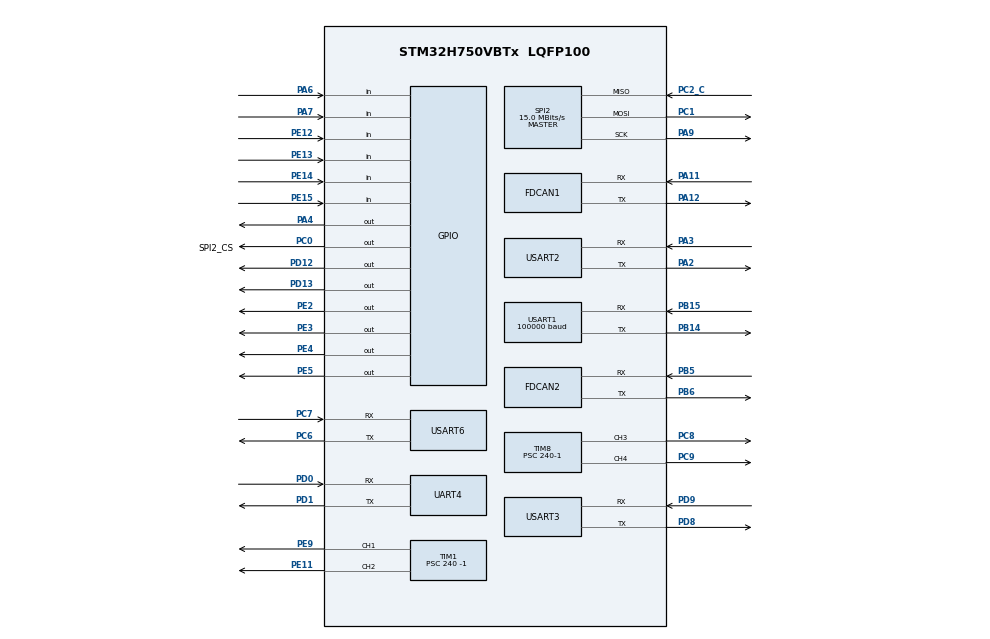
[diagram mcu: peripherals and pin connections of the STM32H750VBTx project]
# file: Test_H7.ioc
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Dma.Request0=USART1_RX
Dma.Request1=USART2_RX
Dma.Request2=USART2_TX
Dma.Request3=USART3_RX
Dma.Request4=USART3_TX
Dma.Request5=USART6_RX
Dma.Request6=USART6_TX
Dma.Request7=USART1_TX
Dma.USART1_RX.0.Direction=DMA_PERIPH_TO_MEMORY
Dma.USART1_RX.0.EventEnable=DISABLE
Dma.USART1_RX.0.FIFOMode=DMA_FIFOMODE_DISABLE
Dma.USART1_RX.0.Instance=DMA2_Stream2
Dma.USART1_RX.0.MemDataAlignment=DMA_MDATAALIGN_BYTE
Dma.USART1_RX.0.MemInc=DMA_MINC_ENABLE
Dma.USART1_RX.0.Mode=DMA_CIRCULAR
Dma.USART1_RX.0.PeriphDataAlignment=DMA_PDATAALIGN_BYTE
Dma.USART1_RX.0.PeriphInc=DMA_PINC_DISABLE
Dma.USART1_RX.0.Polarity=HAL_DMAMUX_REQ_GEN_RISING
Dma.USART1_RX.0.Priority=DMA_PRIORITY_VERY_HIGH
Dma.USART1_RX.0.RequestNumber=1
Dma.USART1_RX.0.SignalID=NONE
Dma.USART1_RX.0.SyncEnable=DISABLE
Dma.USART1_RX.0.SyncPolarity=HAL_DMAMUX_SYNC_NO_EVENT
Dma.USART1_RX.0.SyncRequestNumber=1
Dma.USART1_RX.0.SyncSignalID=NONE
Dma.USART1_TX.7.Direction=DMA_MEMORY_TO_PERIPH
Dma.USART1_TX.7.EventEnable=DISABLE
Dma.USART1_TX.7.FIFOMode=DMA_FIFOMODE_DISABLE
Dma.USART1_TX.7.Instance=DMA1_Stream0
Dma.USART1_TX.7.MemDataAlignment=DMA_MDATAALIGN_BYTE
Dma.USART1_TX.7.MemInc=DMA_MINC_ENABLE
Dma.USART1_TX.7.Mode=DMA_NORMAL
Dma.USART1_TX.7.PeriphDataAlignment=DMA_PDATAALIGN_BYTE
Dma.USART1_TX.7.PeriphInc=DMA_PINC_DISABLE
Dma.USART1_TX.7.Polarity=HAL_DMAMUX_REQ_GEN_RISING
Dma.USART1_TX.7.Priority=DMA_PRIORITY_LOW
Dma.USART1_TX.7.RequestNumber=1
Dma.USART1_TX.7.SignalID=NONE
Dma.USART1_TX.7.SyncEnable=DISABLE
Dma.USART1_TX.7.SyncPolarity=HAL_DMAMUX_SYNC_NO_EVENT
Dma.USART1_TX.7.SyncRequestNumber=1
Dma.USART1_TX.7.SyncSignalID=NONE
Dma.USART2_RX.1.Direction=DMA_PERIPH_TO_MEMORY
Dma.USART2_RX.1.EventEnable=DISABLE
Dma.USART2_RX.1.FIFOMode=DMA_FIFOMODE_DISABLE
Dma.USART2_RX.1.Instance=DMA1_Stream2
Dma.USART2_RX.1.MemDataAlignment=DMA_MDATAALIGN_BYTE
Dma.USART2_RX.1.MemInc=DMA_MINC_ENABLE
Dma.USART2_RX.1.Mode=DMA_CIRCULAR
Dma.USART2_RX.1.PeriphDataAlignment=DMA_PDATAALIGN_BYTE
Dma.USART2_RX.1.PeriphInc=DMA_PINC_DISABLE
Dma.USART2_RX.1.Polarity=HAL_DMAMUX_REQ_GEN_RISING
Dma.USART2_RX.1.Priority=DMA_PRIORITY_HIGH
Dma.USART2_RX.1.RequestNumber=1
Dma.USART2_RX.1.SignalID=NONE
Dma.USART2_RX.1.SyncEnable=DISABLE
Dma.USART2_RX.1.SyncPolarity=HAL_DMAMUX_SYNC_NO_EVENT
Dma.USART2_RX.1.SyncRequestNumber=1
Dma.USART2_RX.1.SyncSignalID=NONE
Dma.USART2_TX.2.Direction=DMA_MEMORY_TO_PERIPH
Dma.USART2_TX.2.EventEnable=DISABLE
Dma.USART2_TX.2.FIFOMode=DMA_FIFOMODE_DISABLE
Dma.USART2_TX.2.Instance=DMA1_Stream4
Dma.USART2_TX.2.MemDataAlignment=DMA_MDATAALIGN_BYTE
Dma.USART2_TX.2.MemInc=DMA_MINC_ENABLE
Dma.USART2_TX.2.Mode=DMA_NORMAL
Dma.USART2_TX.2.PeriphDataAlignment=DMA_PDATAALIGN_BYTE
Dma.USART2_TX.2.PeriphInc=DMA_PINC_DISABLE
Dma.USART2_TX.2.Polarity=HAL_DMAMUX_REQ_GEN_RISING
Dma.USART2_TX.2.Priority=DMA_PRIORITY_HIGH
Dma.USART2_TX.2.RequestNumber=1
Dma.USART2_TX.2.SignalID=NONE
Dma.USART2_TX.2.SyncEnable=DISABLE
Dma.USART2_TX.2.SyncPolarity=HAL_DMAMUX_SYNC_NO_EVENT
Dma.USART2_TX.2.SyncRequestNumber=1
Dma.USART2_TX.2.SyncSignalID=NONE
Dma.USART3_RX.3.Direction=DMA_PERIPH_TO_MEMORY
Dma.USART3_RX.3.EventEnable=DISABLE
Dma.USART3_RX.3.FIFOMode=DMA_FIFOMODE_DISABLE
Dma.USART3_RX.3.Instance=DMA1_Stream1
Dma.USART3_RX.3.MemDataAlignment=DMA_MDATAALIGN_BYTE
Dma.USART3_RX.3.MemInc=DMA_MINC_ENABLE
Dma.USART3_RX.3.Mode=DMA_CIRCULAR
Dma.USART3_RX.3.PeriphDataAlignment=DMA_PDATAALIGN_BYTE
Dma.USART3_RX.3.PeriphInc=DMA_PINC_DISABLE
Dma.USART3_RX.3.Polarity=HAL_DMAMUX_REQ_GEN_RISING
Dma.USART3_RX.3.Priority=DMA_PRIORITY_VERY_HIGH
Dma.USART3_RX.3.RequestNumber=1
Dma.USART3_RX.3.SignalID=NONE
Dma.USART3_RX.3.SyncEnable=DISABLE
Dma.USART3_RX.3.SyncPolarity=HAL_DMAMUX_SYNC_NO_EVENT
Dma.USART3_RX.3.SyncRequestNumber=1
Dma.USART3_RX.3.SyncSignalID=NONE
Dma.USART3_TX.4.Direction=DMA_MEMORY_TO_PERIPH
Dma.USART3_TX.4.EventEnable=DISABLE
Dma.USART3_TX.4.FIFOMode=DMA_FIFOMODE_DISABLE
Dma.USART3_TX.4.Instance=DMA1_Stream3
Dma.USART3_TX.4.MemDataAlignment=DMA_MDATAALIGN_BYTE
Dma.USART3_TX.4.MemInc=DMA_MINC_ENABLE
Dma.USART3_TX.4.Mode=DMA_NORMAL
Dma.USART3_TX.4.PeriphDataAlignment=DMA_PDATAALIGN_BYTE
Dma.USART3_TX.4.PeriphInc=DMA_PINC_DISABLE
Dma.USART3_TX.4.Polarity=HAL_DMAMUX_REQ_GEN_RISING
Dma.USART3_TX.4.Priority=DMA_PRIORITY_VERY_HIGH
Dma.USART3_TX.4.RequestNumber=1
Dma.USART3_TX.4.SignalID=NONE
Dma.USART3_TX.4.SyncEnable=DISABLE
Dma.USART3_TX.4.SyncPolarity=HAL_DMAMUX_SYNC_NO_EVENT
Dma.USART3_TX.4.SyncRequestNumber=1
Dma.USART3_TX.4.SyncSignalID=NONE
Dma.USART6_RX.5.Direction=DMA_PERIPH_TO_MEMORY
Dma.USART6_RX.5.EventEnable=DISABLE
Dma.USART6_RX.5.FIFOMode=DMA_FIFOMODE_DISABLE
Dma.USART6_RX.5.Instance=DMA2_Stream1
Dma.USART6_RX.5.MemDataAlignment=DMA_MDATAALIGN_BYTE
Dma.USART6_RX.5.MemInc=DMA_MINC_ENABLE
Dma.USART6_RX.5.Mode=DMA_CIRCULAR
Dma.USART6_RX.5.PeriphDataAlignment=DMA_PDATAALIGN_BYTE
Dma.USART6_RX.5.PeriphInc=DMA_PINC_DISABLE
Dma.USART6_RX.5.Polarity=HAL_DMAMUX_REQ_GEN_RISING
Dma.USART6_RX.5.Priority=DMA_PRIORITY_VERY_HIGH
Dma.USART6_RX.5.RequestNumber=1
Dma.USART6_RX.5.SignalID=NONE
Dma.USART6_RX.5.SyncEnable=DISABLE
Dma.USART6_RX.5.SyncPolarity=HAL_DMAMUX_SYNC_NO_EVENT
Dma.USART6_RX.5.SyncRequestNumber=1
Dma.USART6_RX.5.SyncSignalID=NONE
Dma.USART6_TX.6.Direction=DMA_MEMORY_TO_PERIPH
Dma.USART6_TX.6.EventEnable=DISABLE
Dma.USART6_TX.6.FIFOMode=DMA_FIFOMODE_DISABLE
Dma.USART6_TX.6.Instance=DMA2_Stream6
Dma.USART6_TX.6.MemDataAlignment=DMA_MDATAALIGN_BYTE
Dma.USART6_TX.6.MemInc=DMA_MINC_ENABLE
Dma.USART6_TX.6.Mode=DMA_NORMAL
Dma.USART6_TX.6.PeriphDataAlignment=DMA_PDATAALIGN_BYTE
Dma.USART6_TX.6.PeriphInc=DMA_PINC_DISABLE
Dma.USART6_TX.6.Polarity=HAL_DMAMUX_REQ_GEN_RISING
Dma.USART6_TX.6.Priority=DMA_PRIORITY_VERY_HIGH
Dma.USART6_TX.6.RequestNumber=1
Dma.USART6_TX.6.SignalID=NONE
Dma.USART6_TX.6.SyncEnable=DISABLE
Dma.USART6_TX.6.SyncPolarity=HAL_DMAMUX_SYNC_NO_EVENT
Dma.USART6_TX.6.SyncRequestNumber=1
Dma.USART6_TX.6.SyncSignalID=NONE
FDCAN1.AutoRetransmission=DISABLE
FDCAN1.DataPrescaler=1
FDCAN1.DataSyncJumpWidth=10
FDCAN1.DataTimeSeg1=29
FDCAN1.DataTimeSeg2=10
FDCAN1.ExtFiltersNbr=1
FDCAN1.FrameFormat=FDCAN_FRAME_FD_BRS
FDCAN1.Mode=FDCAN_MODE_NORMAL
FDCAN1.NominalPrescaler=1
FDCAN1.NominalSyncJumpWidth=8
FDCAN1.NominalTimeSeg1=31
FDCAN1.NominalTimeSeg2=8
FDCAN1.RxBufferSize=FDCAN_DATA_BYTES_8
FDCAN1.RxBuffersNbr=0
FDCAN1.RxFifo0ElmtSize=FDCAN_DATA_BYTES_8
FDCAN1.RxFifo0ElmtsNbr=32
FDCAN1.RxFifo1ElmtSize=FDCAN_DATA_BYTES_8
FDCAN1.RxFifo1ElmtsNbr=0
FDCAN1.StdFiltersNbr=1
FDCAN1.TransmitPause=DISABLE
FDCAN1.TxBuffersNbr=0
FDCAN1.TxElmtSize=FDCAN_DATA_BYTES_8
FDCAN1.TxEventsNbr=0
FDCAN1.TxFifoQueueElmtsNbr=8
FDCAN2.DataSyncJumpWidth=10
FDCAN2.DataTimeSeg1=29
FDCAN2.DataTimeSeg2=10
FDCAN2.ExtFiltersNbr=1
FDCAN2.FrameFormat=FDCAN_FRAME_FD_BRS
FDCAN2.MessageRAMOffset=666
FDCAN2.NominalSyncJumpWidth=8
FDCAN2.NominalTimeSeg1=31
FDCAN2.NominalTimeSeg2=8
FDCAN2.RxFifo0ElmtsNbr=32
FDCAN2.StdFiltersNbr=1
FDCAN2.TxFifoQueueElmtsNbr=8
FREERTOS.Tasks01=defaultTask,0,128,StartDefaultTask,Default,NULL,Dynamic,NULL,NULL;FireTask,1,128,Fire_Task,As external,NULL,Dynamic,NULL,NULL;LedTask,-3,128,Led_Task,As external,NULL,Dynamic,NULL,NULL;DetectTASK,-1,128,Detect_TASK,As external,NULL,Dynamic,NULL,NULL;SAFETASK,1,128,SAFE_TASK,As external,NULL,Dynamic,NULL,NULL;RemoteTask,2,128,Remote_Task,As external,NULL,Dynamic,NULL,NULL
Mcu.Family=STM32H7
Mcu.Name=STM32H750VBTx
Mcu.Package=LQFP100
NVIC.DMA1_Stream0_IRQn=true\:5\:0\:false\:false\:true\:true\:false\:true
NVIC.DMA1_Stream1_IRQn=true\:5\:0\:false\:false\:true\:true\:false\:true
NVIC.DMA1_Stream2_IRQn=true\:5\:0\:false\:false\:true\:false\:false\:true
NVIC.DMA1_Stream3_IRQn=true\:5\:0\:false\:false\:true\:true\:false\:true
NVIC.DMA1_Stream4_IRQn=true\:5\:0\:false\:false\:true\:true\:false\:true
NVIC.DMA2_Stream1_IRQn=true\:5\:0\:false\:false\:true\:false\:false\:true
NVIC.DMA2_Stream2_IRQn=true\:5\:0\:false\:false\:true\:true\:false\:true
NVIC.DMA2_Stream6_IRQn=true\:5\:0\:false\:false\:true\:false\:false\:true
NVIC.FDCAN1_IT0_IRQn=true\:5\:0\:false\:false\:true\:true\:true\:true
NVIC.FDCAN2_IT0_IRQn=true\:5\:0\:false\:false\:true\:true\:true\:true
NVIC.PriorityGroup=NVIC_PRIORITYGROUP_4
NVIC.TIM2_IRQn=true\:15\:0\:false\:false\:true\:false\:false\:true
NVIC.TimeBase=TIM2_IRQn
NVIC.TimeBaseIP=TIM2
NVIC.USART1_IRQn=true\:5\:0\:false\:false\:true\:true\:true\:true
NVIC.USART2_IRQn=true\:5\:0\:false\:false\:true\:true\:true\:true
NVIC.USART3_IRQn=true\:5\:0\:false\:false\:true\:true\:true\:true
NVIC.USART6_IRQn=true\:5\:0\:false\:false\:true\:true\:true\:true
PA11.Mode=FDCAN_Activate
PA11.Signal=FDCAN1_RX
PA12.Mode=FDCAN_Activate
PA12.Signal=FDCAN1_TX
PA13\ (JTMS/SWDIO).Mode=Serial_Wire
PA13\ (JTMS/SWDIO).Signal=DEBUG_JTMS-SWDIO
PA14\ (JTCK/SWCLK).Mode=Serial_Wire
PA14\ (JTCK/SWCLK).Signal=DEBUG_JTCK-SWCLK
PA2.Mode=Asynchronous
PA2.Signal=USART2_TX
PA3.GPIO_PuPd=GPIO_PULLUP
PA3.Mode=Asynchronous
PA3.Signal=USART2_RX
PA4.Signal=GPIO_Output
PA6.GPIO_PuPd=GPIO_PULLDOWN
PA6.Signal=GPIO_Input
PA7.GPIO_PuPd=GPIO_PULLDOWN
PA7.Signal=GPIO_Input
PA9.Mode=Full_Duplex_Master
PA9.Signal=SPI2_SCK
PB14.Mode=Asynchronous
PB14.Signal=USART1_TX
PB15.Mode=Asynchronous
PB15.Signal=USART1_RX
PB5.Mode=FDCAN_Activate
PB5.Signal=FDCAN2_RX
PB6.Mode=FDCAN_Activate
PB6.Signal=FDCAN2_TX
PC0.GPIO_Label=SPI2_CS
PC0.Signal=GPIO_Output
PC1.Mode=Full_Duplex_Master
PC1.Signal=SPI2_MOSI
PC2_C.Mode=Full_Duplex_Master
PC2_C.Signal=SPI2_MISO
PC6.Mode=Asynchronous
PC6.Signal=USART6_TX
PC7.Mode=Asynchronous
PC7.Signal=USART6_RX
PC8.Signal=S_TIM8_CH3
PC9.Signal=S_TIM8_CH4
PD0.Mode=Asynchronous
PD0.Signal=UART4_RX
PD1.Mode=Asynchronous
PD1.Signal=UART4_TX
PD12.GPIO_PuPd=GPIO_PULLUP
PD12.GPIO_Speed=GPIO_SPEED_FREQ_HIGH
PD12.Signal=GPIO_Output
PD13.GPIO_PuPd=GPIO_PULLUP
PD13.GPIO_Speed=GPIO_SPEED_FREQ_HIGH
PD13.Signal=GPIO_Output
PD8.Mode=Asynchronous
PD8.Signal=USART3_TX
PD9.Mode=Asynchronous
PD9.Signal=USART3_RX
PE11.Signal=S_TIM1_CH2
PE12.GPIO_PuPd=GPIO_NOPULL
PE12.Signal=GPIO_Input
PE13.Signal=GPIO_Input
PE14.Signal=GPIO_Input
PE15.Signal=GPIO_Input
PE2.PinState=GPIO_PIN_SET
PE2.Signal=GPIO_Output
PE3.Signal=GPIO_Output
PE4.Signal=GPIO_Output
PE5.Signal=GPIO_Output
PE9.GPIO_PuPd=GPIO_PULLUP
PE9.Signal=S_TIM1_CH1
PH0-OSC_IN\ (PH0).Mode=HSE-External-Oscillator
PH0-OSC_IN\ (PH0).Signal=RCC_OSC_IN
PH1-OSC_OUT\ (PH1).Mode=HSE-External-Oscillator
PH1-OSC_OUT\ (PH1).Signal=RCC_OSC_OUT
ProjectManager.HeapSize=0x200
ProjectManager.StackSize=0x400
ProjectManager.TargetToolchain=MDK-ARM V5.32
RCC.ADCFreq_Value=60000000
RCC.APB1Freq_Value=120000000
RCC.APB2Freq_Value=120000000
RCC.APB3Freq_Value=120000000
RCC.APB4Freq_Value=120000000
RCC.CKPERSourceSelection=RCC_CLKPSOURCE_HSE
RCC.CortexFreq_Value=480000000
RCC.D1PPRE=RCC_APB3_DIV2
RCC.D2PPRE1=RCC_APB1_DIV2
RCC.D2PPRE2=RCC_APB2_DIV2
RCC.D3PPRE=RCC_APB4_DIV2
RCC.DIVM1=5
RCC.DIVM2=25
RCC.DIVM3=25
RCC.DIVN1=192
RCC.DIVN2=480
RCC.DIVN3=480
RCC.DIVP2=8
RCC.DIVQ1=24
RCC.HCLKFreq_Value=240000000
RCC.HPRE=RCC_HCLK_DIV2
RCC.PLLFRACN=0
RCC.PLLSourceVirtual=RCC_PLLSOURCE_HSE
RCC.SPI123CLockSelection=RCC_SPI123CLKSOURCE_PLL2
RCC.SYSCLKFreq_VALUE=480000000
RCC.SYSCLKSource=RCC_SYSCLKSOURCE_PLLCLK
RCC.USBFreq_Value=40000000
SH.S_TIM1_CH1.0=TIM1_CH1,PWM Generation1 CH1
SH.S_TIM1_CH2.0=TIM1_CH2,PWM Generation2 CH2
SH.S_TIM8_CH3.0=TIM8_CH3,PWM Generation3 CH3
SH.S_TIM8_CH4.0=TIM8_CH4,PWM Generation4 CH4
SPI2.BaudRatePrescaler=SPI_BAUDRATEPRESCALER_4
SPI2.CalculateBaudRate=15.0 MBits/s
SPI2.DataSize=SPI_DATASIZE_8BIT
SPI2.Direction=SPI_DIRECTION_2LINES
SPI2.Mode=SPI_MODE_MASTER
SPI2.VirtualType=VM_MASTER
TIM1.Channel-PWM\ Generation1\ CH1=TIM_CHANNEL_1
TIM1.Channel-PWM\ Generation2\ CH2=TIM_CHANNEL_2
TIM1.Period=2100
TIM1.Prescaler=240 -1 
TIM8.Channel-PWM\ Generation3\ CH3=TIM_CHANNEL_3
TIM8.Channel-PWM\ Generation4\ CH4=TIM_CHANNEL_4
TIM8.Period=2100
TIM8.Prescaler=240-1
USART1.BaudRate=100000
USART1.Parity=PARITY_EVEN
USART1.VirtualMode-Asynchronous=VM_ASYNC
USART1.WordLength=WORDLENGTH_9B
USART2.VirtualMode-Asynchronous=VM_ASYNC
USART3.VirtualMode-Asynchronous=VM_ASYNC
USART6.VirtualMode=VM_ASYNC
VP_FREERTOS_VS_CMSIS_V1.Mode=CMSIS_V1
VP_RNG_VS_RNG.Mode=RNG_Activate
VP_SYS_VS_tim2.Mode=TIM2
board=custom

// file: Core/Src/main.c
/* USER CODE BEGIN Header */
/**
  ******************************************************************************
  * @file           : main.c
  * @brief          : Main program body
  ******************************************************************************
  * @attention
  *
  * <h2><center>&copy; Copyright (c) 2021 STMicroelectronics.
  * All rights reserved.</center></h2>
  *
  * This software component is licensed by ST under BSD 3-Clause license,
  * the "License"; You may not use this file except in compliance with the
  * License. You may obtain a copy of the License at:
  *                        opensource.org/licenses/BSD-3-Clause
  *
  ******************************************************************************
  */
/* USER CODE END Header */
#include "main.h"
#include "cmsis_os.h"
#include "dma.h"
#include "fdcan.h"
#include "rng.h"
#include "spi.h"
#include "tim.h"
#include "usart.h"
#include "gpio.h"

/* USER CODE BEGIN Includes */
#include "SysInit.h"
/* USER CODE END Includes */

/* USER CODE BEGIN PTD */

/************************** Dongguan-University of Technology -ACE**************************
 *@project   SentryChassis
 *@Author    Dongguan-University of Technology  ACE  Ҷ��͢Y.Z.T.
 *@Date      2022-01-07

                    P                          :u7  :Ii              .
                   QBQ                     sQBBQBB  PBBBBQI.        XQBBBBBBBBBQBBBBBBBBBBBBM
                  bBBBZ                 .MQBQBBBQB  5BBBBBBBBi      uBBBBBBBBBQBBBBBBBBBQBBBP
                 bBBQQB5               XBBBRQQBBBP  sQBQBQQBBBZ     IBBBBBBBBBBBBBBBBBBBBBBBD
                 rBBgRQBY             BBQQRBBQr        rgBBBQr
               .  iBBgRQB7           BBQRgBQ:            iE.
              :BY  7BBgRQB:         sBQMgBB
             .BBB:  uBBgRBB.        BBMDQQ:                         rSU57  UQPdPbPPPPqPPbPdQs
             BBQBB:  XBQgRBB        QBggQB                          sBEQ1  QBBBBQBBBBBBBBBBBZ
            BBQgBBB   KBRDRBB       BBgDBB                          jBDQU  QBBBBBBBBBBBQBBBBg
           BBQgRBB     dQggQBB      BBggQB.                         iXJS7  uDK5XXK5KXKXXSSXg7
          gBQgRQB   BBggQDggQBQ     YBQDMBB
         PBQgRBB   BBBBBRQgMgQBg     BBQgRBB:            iZ:
        2BQgMBB.  BBBBBBBBBQRgQBK     BBBRQBBQL.      .rRBBQBr       ..                   ..
       vQBgRQB:  :uriiiiiirBQQgBB1     XQBQQQBBBBE  uBQBQBQBBBD     SBBBBBBBBBBBBBBBBBBBQBBBD
      7QBQBBBr             :BBBQBBY     .ZBQBBBBBB  qBBQBBBBB:      UBBBBQBBBBBBBBBBBBBBBBBBd
     LBBBBBBJ               7BBBBBQu       YRBBBQB  KBBBBBJ.        IBQBBBBBQBBBBBBBBBBBBBBBZ
                                                7i  .7.
*************************** Dongguan-University of Technology -ACE**************************/

/* USER CODE END PTD */

void SystemClock_Config(void);
void MX_FREERTOS_Init(void);

int main(void)
{

  /* MCU Configuration--------------------------------------------------------*/

  /* Reset of all peripherals, Initializes the Flash interface and the Systick. */
  HAL_Init();

  /* Configure the system clock */
  SystemClock_Config();

  /* Initialize all configured peripherals */
  MX_GPIO_Init();
  MX_USART1_UART_Init();
  MX_UART4_Init();
  MX_SPI2_Init();
  MX_FDCAN1_Init();
  MX_DMA_Init();
  MX_RNG_Init();
  MX_FDCAN2_Init();
  MX_USART2_UART_Init();
  MX_USART3_UART_Init();
  MX_USART6_UART_Init();
  MX_TIM1_Init();
  MX_TIM8_Init();
  /* USER CODE BEGIN 2 */

	System_init();			//ȫ�ֳ�ʼ��
  /* USER CODE END 2 */

  /* Call init function for freertos objects (in freertos.c) */
  MX_FREERTOS_Init();
  /* Start scheduler */
  osKernelStart();

  /* We should never get here as control is now taken by the scheduler */
  /* Infinite loop */
  while (1)
  {

  }
}

void SystemClock_Config(void)
{
  RCC_OscInitTypeDef RCC_OscInitStruct = {0};
  RCC_ClkInitTypeDef RCC_ClkInitStruct = {0};

  /** Supply configuration update enable
  */
  HAL_PWREx_ConfigSupply(PWR_LDO_SUPPLY);
  /** Configure the main internal regulator output voltage
  */
  __HAL_PWR_VOLTAGESCALING_CONFIG(PWR_REGULATOR_VOLTAGE_SCALE0);

  while(!__HAL_PWR_GET_FLAG(PWR_FLAG_VOSRDY)) {}
  /** Macro to configure the PLL clock source
  */
  __HAL_RCC_PLL_PLLSOURCE_CONFIG(RCC_PLLSOURCE_HSE);
  /** Initializes the RCC Oscillators according to the specified parameters
  * in the RCC_OscInitTypeDef structure.
  */
  RCC_OscInitStruct.OscillatorType = RCC_OSCILLATORTYPE_HSI48|RCC_OSCILLATORTYPE_HSE;
  RCC_OscInitStruct.HSEState = RCC_HSE_ON;
  RCC_OscInitStruct.HSI48State = RCC_HSI48_ON;
  RCC_OscInitStruct.PLL.PLLState = RCC_PLL_ON;
  RCC_OscInitStruct.PLL.PLLSource = RCC_PLLSOURCE_HSE;
  RCC_OscInitStruct.PLL.PLLM = 5;
  RCC_OscInitStruct.PLL.PLLN = 192;
  RCC_OscInitStruct.PLL.PLLP = 2;
  RCC_OscInitStruct.PLL.PLLQ = 24;
  RCC_OscInitStruct.PLL.PLLR = 2;
  RCC_OscInitStruct.PLL.PLLRGE = RCC_PLL1VCIRANGE_2;
  RCC_OscInitStruct.PLL.PLLVCOSEL = RCC_PLL1VCOWIDE;
  RCC_OscInitStruct.PLL.PLLFRACN = 0;
  if (HAL_RCC_OscConfig(&RCC_OscInitStruct) != HAL_OK)
  {
    Error_Handler();
  }
  /** Initializes the CPU, AHB and APB buses clocks
  */
  RCC_ClkInitStruct.ClockType = RCC_CLOCKTYPE_HCLK|RCC_CLOCKTYPE_SYSCLK
                              |RCC_CLOCKTYPE_PCLK1|RCC_CLOCKTYPE_PCLK2
                              |RCC_CLOCKTYPE_D3PCLK1|RCC_CLOCKTYPE_D1PCLK1;
  RCC_ClkInitStruct.SYSCLKSource = RCC_SYSCLKSOURCE_PLLCLK;
  RCC_ClkInitStruct.SYSCLKDivider = RCC_SYSCLK_DIV1;
  RCC_ClkInitStruct.AHBCLKDivider = RCC_HCLK_DIV2;
  RCC_ClkInitStruct.APB3CLKDivider = RCC_APB3_DIV2;
  RCC_ClkInitStruct.APB1CLKDivider = RCC_APB1_DIV2;
  RCC_ClkInitStruct.APB2CLKDivider = RCC_APB2_DIV2;
  RCC_ClkInitStruct.APB4CLKDivider = RCC_APB4_DIV2;

  if (HAL_RCC_ClockConfig(&RCC_ClkInitStruct, FLASH_LATENCY_4) != HAL_OK)
  {
    Error_Handler();
  }
}

void HAL_TIM_PeriodElapsedCallback(TIM_HandleTypeDef *htim)
{
  if (htim->Instance == TIM2) {
    HAL_IncTick();
  }
}

void Error_Handler(void)
{
  __disable_irq();
  while (1)
  {
  }
}

/************************ (C) COPYRIGHT STMicroelectronics *****END OF FILE****/

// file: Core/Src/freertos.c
/* USER CODE BEGIN Header */
/**
  ******************************************************************************
  * File Name          : freertos.c
  * Description        : Code for freertos applications
  ******************************************************************************
  * @attention
  *
  * <h2><center>&copy; Copyright (c) 2022 STMicroelectronics.
  * All rights reserved.</center></h2>
  *
  * This software component is licensed by ST under Ultimate Liberty license
  * SLA0044, the "License"; You may not use this file except in compliance with
  * the License. You may obtain a copy of the License at:
  *                             www.st.com/SLA0044
  *
  ******************************************************************************
  */
/* USER CODE END Header */

#include "FreeRTOS.h"
#include "task.h"
#include "main.h"
#include "cmsis_os.h"

osThreadId defaultTaskHandle;
osThreadId FireTaskHandle;
osThreadId LedTaskHandle;
osThreadId DetectTASKHandle;
osThreadId SAFETASKHandle;
osThreadId RemoteTaskHandle;

void StartDefaultTask(void const * argument);
extern void Fire_Task(void const * argument);
extern void Led_Task(void const * argument);
extern void Detect_TASK(void const * argument);
extern void SAFE_TASK(void const * argument);
extern void Remote_Task(void const * argument);

void MX_FREERTOS_Init(void); /* (MISRA C 2004 rule 8.1) */

/* GetIdleTaskMemory prototype (linked to static allocation support) */
void vApplicationGetIdleTaskMemory( StaticTask_t **ppxIdleTaskTCBBuffer, StackType_t **ppxIdleTaskStackBuffer, uint32_t *pulIdleTaskStackSize );

/* USER CODE BEGIN GET_IDLE_TASK_MEMORY */
static StaticTask_t xIdleTaskTCBBuffer;
static StackType_t xIdleStack[configMINIMAL_STACK_SIZE];

void vApplicationGetIdleTaskMemory( StaticTask_t **ppxIdleTaskTCBBuffer, StackType_t **ppxIdleTaskStackBuffer, uint32_t *pulIdleTaskStackSize )
{
  *ppxIdleTaskTCBBuffer = &xIdleTaskTCBBuffer;
  *ppxIdleTaskStackBuffer = &xIdleStack[0];
  *pulIdleTaskStackSize = configMINIMAL_STACK_SIZE;
  /* place for user code */
}
/* USER CODE END GET_IDLE_TASK_MEMORY */

void MX_FREERTOS_Init(void) {

  /* Create the thread(s) */
  /* definition and creation of defaultTask */
  osThreadDef(defaultTask, StartDefaultTask, osPriorityNormal, 0, 128);
  defaultTaskHandle = osThreadCreate(osThread(defaultTask), NULL);

  /* definition and creation of FireTask */
  osThreadDef(FireTask, Fire_Task, osPriorityAboveNormal, 0, 128);
  FireTaskHandle = osThreadCreate(osThread(FireTask), NULL);

  /* definition and creation of LedTask */
  osThreadDef(LedTask, Led_Task, osPriorityIdle, 0, 128);
  LedTaskHandle = osThreadCreate(osThread(LedTask), NULL);

  /* definition and creation of DetectTASK */
  osThreadDef(DetectTASK, Detect_TASK, osPriorityBelowNormal, 0, 128);
  DetectTASKHandle = osThreadCreate(osThread(DetectTASK), NULL);

  /* definition and creation of SAFETASK */
  osThreadDef(SAFETASK, SAFE_TASK, osPriorityAboveNormal, 0, 128);
  SAFETASKHandle = osThreadCreate(osThread(SAFETASK), NULL);

  /* definition and creation of RemoteTask */
  osThreadDef(RemoteTask, Remote_Task, osPriorityHigh, 0, 128);
  RemoteTaskHandle = osThreadCreate(osThread(RemoteTask), NULL);

}

void StartDefaultTask(void const * argument)
{
  for(;;)
  {
    osDelay(1);
  }
}

/************************ (C) COPYRIGHT STMicroelectronics *****END OF FILE****/
